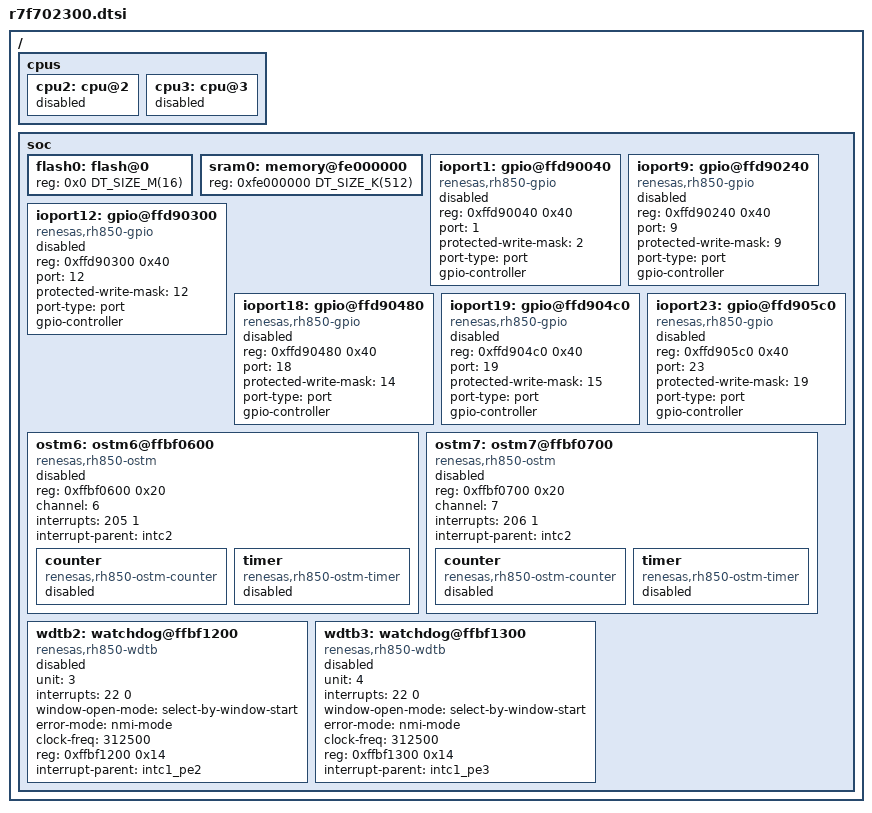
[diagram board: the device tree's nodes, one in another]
/*
 * Copyright (c) 2026 Renesas Electronics Corporation
 *
 * SPDX-License-Identifier: Apache-2.0
 */

#include <rh850/renesas/rh850u2a/r7f702301.dtsi>

/* Peripheral definition following RH850/U2A 516pin devices */
/ {
	cpus {
		cpu2: cpu@2 {
			status = "disabled";
		};

		cpu3: cpu@3 {
			status = "disabled";
		};
	};

	soc {
		flash0: flash@0 {
			reg = <0x0 DT_SIZE_M(16)>;
		};

		sram0: memory@fe000000 {
			reg = <0xfe000000 DT_SIZE_K(512)>;
		};

		ioport1: gpio@ffd90040 {
			compatible = "renesas,rh850-gpio";
			reg = <0xffd90040 0x40>;
			port = <1>;
			protected-write-mask = <2>;
			port-type = "port";
			#gpio-cells = <2>;
			gpio-controller;
			status = "disabled";
		};

		ioport9: gpio@ffd90240 {
			compatible = "renesas,rh850-gpio";
			reg = <0xffd90240 0x40>;
			port = <9>;
			protected-write-mask = <9>;
			port-type = "port";
			#gpio-cells = <2>;
			gpio-controller;
			status = "disabled";
		};

		ioport12: gpio@ffd90300 {
			compatible = "renesas,rh850-gpio";
			reg = <0xffd90300 0x40>;
			port = <12>;
			protected-write-mask = <12>;
			port-type = "port";
			#gpio-cells = <2>;
			gpio-controller;
			status = "disabled";
		};

		ioport18: gpio@ffd90480 {
			compatible = "renesas,rh850-gpio";
			reg = <0xffd90480 0x40>;
			port = <18>;
			protected-write-mask = <14>;
			port-type = "port";
			#gpio-cells = <2>;
			gpio-controller;
			status = "disabled";
		};

		ioport19: gpio@ffd904c0 {
			compatible = "renesas,rh850-gpio";
			reg = <0xffd904c0 0x40>;
			port = <19>;
			protected-write-mask = <15>;
			port-type = "port";
			#gpio-cells = <2>;
			gpio-controller;
			status = "disabled";
		};

		ioport23: gpio@ffd905c0 {
			compatible = "renesas,rh850-gpio";
			reg = <0xffd905c0 0x40>;
			port = <23>;
			protected-write-mask = <19>;
			port-type = "port";
			#gpio-cells = <2>;
			gpio-controller;
			status = "disabled";
		};

		ostm6: ostm6@ffbf0600 {
			compatible = "renesas,rh850-ostm";
			reg = <0xffbf0600 0x20>;
			channel = <6>;
			interrupts = <205 1>;
			interrupt-names = "overflow";
			interrupt-parent = <&intc2>;
			status = "disabled";

			counter {
				compatible = "renesas,rh850-ostm-counter";
				status = "disabled";
			};

			timer {
				compatible = "renesas,rh850-ostm-timer";
				status = "disabled";
			};
		};

		ostm7: ostm7@ffbf0700 {
			compatible = "renesas,rh850-ostm";
			reg = <0xffbf0700 0x20>;
			channel = <7>;
			interrupts = <206 1>;
			interrupt-names = "overflow";
			interrupt-parent = <&intc2>;
			status = "disabled";

			counter {
				compatible = "renesas,rh850-ostm-counter";
				status = "disabled";
			};

			timer {
				compatible = "renesas,rh850-ostm-timer";
				status = "disabled";
			};
		};

		wdtb2: watchdog@ffbf1200 {
			unit = <3>;
			compatible = "renesas,rh850-wdtb";
			interrupts = <22 0>;
			window-open-mode = "select-by-window-start";
			error-mode = "nmi-mode";
			clock-freq = <312500>;
			reg = <0xffbf1200 0x14>;
			interrupt-parent = <&intc1_pe2>;
			status = "disabled";
		};

		wdtb3: watchdog@ffbf1300 {
			unit = <4>;
			compatible = "renesas,rh850-wdtb";
			interrupts = <22 0>;
			window-open-mode = "select-by-window-start";
			error-mode = "nmi-mode";
			clock-freq = <312500>;
			reg = <0xffbf1300 0x14>;
			interrupt-parent = <&intc1_pe3>;
			status = "disabled";
		};
	};
};
